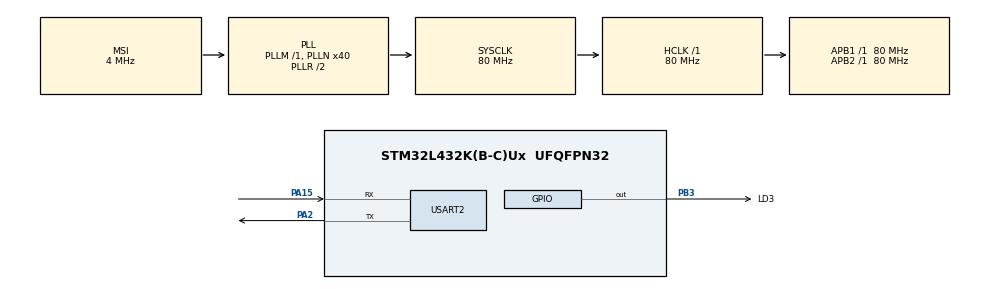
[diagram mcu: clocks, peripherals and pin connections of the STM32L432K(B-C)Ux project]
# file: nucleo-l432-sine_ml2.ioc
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Mcu.Family=STM32L4
Mcu.Name=STM32L432K(B-C)Ux
Mcu.Package=UFQFPN32
NVIC.PriorityGroup=NVIC_PRIORITYGROUP_4
PA13\ (JTMS-SWDIO).Mode=Serial_Wire
PA13\ (JTMS-SWDIO).Signal=SYS_JTMS-SWDIO
PA14\ (JTCK-SWCLK).Mode=Serial_Wire
PA14\ (JTCK-SWCLK).Signal=SYS_JTCK-SWCLK
PA15\ (JTDI).Mode=Asynchronous
PA15\ (JTDI).Signal=USART2_RX
PA2.Mode=Asynchronous
PA2.Signal=USART2_TX
PB3\ (JTDO-TRACESWO).GPIO_Label=LD3
PB3\ (JTDO-TRACESWO).Signal=GPIO_Output
PC14-OSC32_IN\ (PC14).Mode=LSE-External-Oscillator
PC14-OSC32_IN\ (PC14).Signal=RCC_OSC32_IN
PC15-OSC32_OUT\ (PC15).Mode=LSE-External-Oscillator
PC15-OSC32_OUT\ (PC15).Signal=RCC_OSC32_OUT
ProjectManager.HeapSize=0x800
ProjectManager.StackSize=0x800
ProjectManager.TargetToolchain=STM32CubeIDE
RCC.ADCFreq_Value=16000000
RCC.AHBFreq_Value=80000000
RCC.APB1Freq_Value=80000000
RCC.APB1TimFreq_Value=80000000
RCC.APB2Freq_Value=80000000
RCC.APB2TimFreq_Value=80000000
RCC.CortexFreq_Value=80000000
RCC.HCLKFreq_Value=80000000
RCC.HSE_VALUE=8000000
RCC.HSI48_VALUE=48000000
RCC.HSI_VALUE=16000000
RCC.MSI_VALUE=4000000
RCC.PLLN=40
RCC.SYSCLKFreq_VALUE=80000000
RCC.SYSCLKSource=RCC_SYSCLKSOURCE_PLLCLK
RCC.USBFreq_Value=16000000
RCC.VCOOutputFreq_Value=160000000
STMicroelectronics.X-CUBE-AI.10.0.0.ActivationBufferSizeList=1940
STMicroelectronics.X-CUBE-AI.10.0.0.ActivationBuffers=pool0
STMicroelectronics.X-CUBE-AI.10.0.0.ActivationNames=pool0
STMicroelectronics.X-CUBE-AI.10.0.0.ActivationSizes=AI_SINE_MODEL_DATA_ACTIVATION_1_SIZE
STMicroelectronics.X-CUBE-AI.10.0.0.HeapSize=0x800
STMicroelectronics.X-CUBE-AI.10.0.0.InternalRamActivationBufferMaxSize=AI_SINE_MODEL_DATA_ACTIVATIONS_SIZE
STMicroelectronics.X-CUBE-AI.10.0.0.LatestDirectoryUsed-c6a9cc019ab6260dbbfc86d1c0844e88c55a9913909963e01f907c19b2b0253b=C\:\\Users\\bausch\\Downloads
STMicroelectronics.X-CUBE-AI.10.0.0.MaximumNumberOfInputLayer=1
STMicroelectronics.X-CUBE-AI.10.0.0.MaximumNumberOfOutputLayer=1
STMicroelectronics.X-CUBE-AI.10.0.0.MaximumSizeOfInputLayer=1
STMicroelectronics.X-CUBE-AI.10.0.0.MaximumSizeOfOutputLayer=1
STMicroelectronics.X-CUBE-AI.10.0.0.ModelActualCompression-c6a9cc019ab6260dbbfc86d1c0844e88c55a9913909963e01f907c19b2b0253b=0.0
STMicroelectronics.X-CUBE-AI.10.0.0.ModelCompression-c6a9cc019ab6260dbbfc86d1c0844e88c55a9913909963e01f907c19b2b0253b=None
STMicroelectronics.X-CUBE-AI.10.0.0.ModelFlashOccupation-c6a9cc019ab6260dbbfc86d1c0844e88c55a9913909963e01f907c19b2b0253b=10130
STMicroelectronics.X-CUBE-AI.10.0.0.ModelHashList=c6a9cc019ab6260dbbfc86d1c0844e88c55a9913909963e01f907c19b2b0253b
STMicroelectronics.X-CUBE-AI.10.0.0.ModelKind-c6a9cc019ab6260dbbfc86d1c0844e88c55a9913909963e01f907c19b2b0253b=TFLITE
STMicroelectronics.X-CUBE-AI.10.0.0.ModelMacc-c6a9cc019ab6260dbbfc86d1c0844e88c55a9913909963e01f907c19b2b0253b=353
STMicroelectronics.X-CUBE-AI.10.0.0.ModelName-c6a9cc019ab6260dbbfc86d1c0844e88c55a9913909963e01f907c19b2b0253b=sine_model
STMicroelectronics.X-CUBE-AI.10.0.0.ModelNameList=sine_model
STMicroelectronics.X-CUBE-AI.10.0.0.ModelRamOccupation-c6a9cc019ab6260dbbfc86d1c0844e88c55a9913909963e01f907c19b2b0253b=1940
STMicroelectronics.X-CUBE-AI.10.0.0.ModelStructureFile-c6a9cc019ab6260dbbfc86d1c0844e88c55a9913909963e01f907c19b2b0253b=C\:\\Users\\bausch\\Downloads\\sine_model.tflite
STMicroelectronics.X-CUBE-AI.10.0.0.ModelType-c6a9cc019ab6260dbbfc86d1c0844e88c55a9913909963e01f907c19b2b0253b=STM32Cube.AI MCU runtime
STMicroelectronics.X-CUBE-AI.10.0.0.ReadyForCodeGeneration=true
STMicroelectronics.X-CUBE-AI.10.0.0.StackSize=0x800
STMicroelectronics.X-CUBE-AI.10.0.0.WorkingBufferStartAddrList=0xFFFFFFFF
STMicroelectronics.X-CUBE-AI.10.0.0.XAaCUBEAaAICcArtificialOoIntelligenceJjCore=true
STMicroelectronics.X-CUBE-AI.10.0.0.copyWeightToRam=false
STMicroelectronics.X-CUBE-AI.10.0.0.copyWeightToRam-c6a9cc019ab6260dbbfc86d1c0844e88c55a9913909963e01f907c19b2b0253b=false
STMicroelectronics.X-CUBE-AI.10.0.0.customLayerConfigEnabled=false
STMicroelectronics.X-CUBE-AI.10.0.0.customLayerConfigEnabled-c6a9cc019ab6260dbbfc86d1c0844e88c55a9913909963e01f907c19b2b0253b=false
STMicroelectronics.X-CUBE-AI.10.0.0.noOnnxIoTranspose=false
STMicroelectronics.X-CUBE-AI.10.0.0.noOnnxIoTranspose-c6a9cc019ab6260dbbfc86d1c0844e88c55a9913909963e01f907c19b2b0253b=false
STMicroelectronics.X-CUBE-AI.10.0.0.useInputAllocation=true
STMicroelectronics.X-CUBE-AI.10.0.0.useInputAllocation-c6a9cc019ab6260dbbfc86d1c0844e88c55a9913909963e01f907c19b2b0253b=true
STMicroelectronics.X-CUBE-AI.10.0.0.useOutputAllocation=true
STMicroelectronics.X-CUBE-AI.10.0.0.useOutputAllocation-c6a9cc019ab6260dbbfc86d1c0844e88c55a9913909963e01f907c19b2b0253b=true
TIM16.Prescaler=80-1
USART2.VirtualMode-Asynchronous=VM_ASYNC
VP_STMicroelectronics.X-CUBE-AI_VS_ArtificialOoIntelligenceJjXAaCUBEAaAI_10.0.0.Mode=ArtificialOoIntelligenceJjXAaCUBEAaAI
VP_TIM16_VS_ClockSourceINT.Mode=Enable_Timer
board=custom

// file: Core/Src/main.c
/* USER CODE BEGIN Header */
/**
  ******************************************************************************
  * @file           : main.c
  * @brief          : Main program body
  ******************************************************************************
  * @attention
  *
  * Copyright (c) 2025 STMicroelectronics.
  * All rights reserved.
  *
  * This software is licensed under terms that can be found in the LICENSE file
  * in the root directory of this software component.
  * If no LICENSE file comes with this software, it is provided AS-IS.
  *
  ******************************************************************************
  */
/* USER CODE END Header */
#include "main.h"

/* USER CODE BEGIN Includes */
#include <stdio.h>

#include "sine_model.h"
#include "sine_model_data.h"
/* USER CODE END Includes */

TIM_HandleTypeDef htim16;

UART_HandleTypeDef huart2;

/* USER CODE BEGIN PV */
// memory used to hold intermediate values for neural network
AI_ALIGNED(4) ai_u8 activations[AI_SINE_MODEL_DATA_ACTIVATIONS_SIZE];
AI_ALIGNED(4) ai_u8 in_data[AI_SINE_MODEL_IN_1_SIZE_BYTES];
AI_ALIGNED(4) ai_u8 out_data[AI_SINE_MODEL_OUT_1_SIZE_BYTES];
/* USER CODE END PV */

void SystemClock_Config(void);
static void MX_GPIO_Init(void);
static void MX_USART2_UART_Init(void);
static void MX_TIM16_Init(void);

int main(void)
{

  /* USER CODE BEGIN 1 */
  // pointer to model
  ai_handle network = AI_HANDLE_NULL;

  // pointer to structs holding data and info about data
  // like tensor height, width and channels
  ai_buffer *ai_input;
  ai_buffer *ai_output;

  // helper variables
  ai_error err;
  ai_network_report report;
  ai_i32 nbatch;

  /* USER CODE END 1 */

  /* MCU Configuration--------------------------------------------------------*/

  /* Reset of all peripherals, Initializes the Flash interface and the Systick. */
  HAL_Init();

  /* Configure the system clock */
  SystemClock_Config();

  /* USER CODE BEGIN SysInit */
  HAL_Delay(3); // wait until LSE is stable

  /* USER CODE END SysInit */

  /* Initialize all configured peripherals */
  MX_GPIO_Init();
  MX_USART2_UART_Init();
  MX_TIM16_Init();
  /* USER CODE BEGIN 2 */

  printf("STM32 CubeAI Demo: Sinusfunktion\r\n");

  HAL_TIM_Base_Start(&htim16);
  uint32_t timestamp;
  uint32_t duration;

  // pointer to activations
  const ai_handle acts[] = {activations};

  // create instance of neural network
  err = ai_sine_model_create_and_init(&network, acts, NULL);

  // check for errors
  if (err.type != AI_ERROR_NONE) {
      printf("Error: ai_sine_model_create_and_init()\r\n");
  } else {
      printf("Success: model created and initialized\r\n");
  }

  if (ai_sine_model_get_report(network, &report) != true) {
      printf("Error: failed to get report\r\n");
  }

  ai_input  = &report.inputs[0];
  ai_output = &report.outputs[0];

  // link inputs and outputs to the model
  ai_input[0].data  = AI_HANDLE_PTR(in_data);
  ai_output[0].data = AI_HANDLE_PTR(out_data);

  float x_val = 1.5;
  float y_val;

  // convert input variable to ai_float
  for (uint8_t i=0; i < AI_SINE_MODEL_IN_1_SIZE; i++) {
	((ai_float*)in_data)[i] = (ai_float)x_val;
  }

  // Get current timestamp
  timestamp = htim16.Instance->CNT;

  // run inference
  nbatch = ai_sine_model_run(network, ai_input, ai_output);

  // Calc duration
  duration = htim16.Instance->CNT - timestamp;

  if (nbatch != 1) {
	printf("Error: could not run inference\r\n");
  }

  // convert output from model to float
  y_val = ((float*)out_data)[0];

  printf("x=%.2f | y=%.3f | Duration: %.3f ms\r\n", x_val, y_val, (duration/1000.0));

  /* USER CODE END 2 */

  /* Infinite loop */
  while (1)
  {

  }
}

void SystemClock_Config(void)
{
  RCC_OscInitTypeDef RCC_OscInitStruct = {0};
  RCC_ClkInitTypeDef RCC_ClkInitStruct = {0};

  /** Configure the main internal regulator output voltage
  */
  if (HAL_PWREx_ControlVoltageScaling(PWR_REGULATOR_VOLTAGE_SCALE1) != HAL_OK)
  {
    Error_Handler();
  }

  /** Configure LSE Drive Capability
  */
  HAL_PWR_EnableBkUpAccess();
  __HAL_RCC_LSEDRIVE_CONFIG(RCC_LSEDRIVE_LOW);

  /** Initializes the RCC Oscillators according to the specified parameters
  * in the RCC_OscInitTypeDef structure.
  */
  RCC_OscInitStruct.OscillatorType = RCC_OSCILLATORTYPE_LSE|RCC_OSCILLATORTYPE_MSI;
  RCC_OscInitStruct.LSEState = RCC_LSE_ON;
  RCC_OscInitStruct.MSIState = RCC_MSI_ON;
  RCC_OscInitStruct.MSICalibrationValue = 0;
  RCC_OscInitStruct.MSIClockRange = RCC_MSIRANGE_6;
  RCC_OscInitStruct.PLL.PLLState = RCC_PLL_ON;
  RCC_OscInitStruct.PLL.PLLSource = RCC_PLLSOURCE_MSI;
  RCC_OscInitStruct.PLL.PLLM = 1;
  RCC_OscInitStruct.PLL.PLLN = 40;
  RCC_OscInitStruct.PLL.PLLP = RCC_PLLP_DIV7;
  RCC_OscInitStruct.PLL.PLLQ = RCC_PLLQ_DIV2;
  RCC_OscInitStruct.PLL.PLLR = RCC_PLLR_DIV2;
  if (HAL_RCC_OscConfig(&RCC_OscInitStruct) != HAL_OK)
  {
    Error_Handler();
  }

  /** Initializes the CPU, AHB and APB buses clocks
  */
  RCC_ClkInitStruct.ClockType = RCC_CLOCKTYPE_HCLK|RCC_CLOCKTYPE_SYSCLK
                              |RCC_CLOCKTYPE_PCLK1|RCC_CLOCKTYPE_PCLK2;
  RCC_ClkInitStruct.SYSCLKSource = RCC_SYSCLKSOURCE_PLLCLK;
  RCC_ClkInitStruct.AHBCLKDivider = RCC_SYSCLK_DIV1;
  RCC_ClkInitStruct.APB1CLKDivider = RCC_HCLK_DIV1;
  RCC_ClkInitStruct.APB2CLKDivider = RCC_HCLK_DIV1;

  if (HAL_RCC_ClockConfig(&RCC_ClkInitStruct, FLASH_LATENCY_4) != HAL_OK)
  {
    Error_Handler();
  }

  /** Enable MSI Auto calibration
  */
  HAL_RCCEx_EnableMSIPLLMode();
}

static void MX_TIM16_Init(void)
{

  htim16.Instance = TIM16;
  htim16.Init.Prescaler = 80-1;
  htim16.Init.CounterMode = TIM_COUNTERMODE_UP;
  htim16.Init.Period = 65535;
  htim16.Init.ClockDivision = TIM_CLOCKDIVISION_DIV1;
  htim16.Init.RepetitionCounter = 0;
  htim16.Init.AutoReloadPreload = TIM_AUTORELOAD_PRELOAD_DISABLE;
  if (HAL_TIM_Base_Init(&htim16) != HAL_OK)
  {
    Error_Handler();
  }

}

static void MX_USART2_UART_Init(void)
{

  huart2.Instance = USART2;
  huart2.Init.BaudRate = 115200;
  huart2.Init.WordLength = UART_WORDLENGTH_8B;
  huart2.Init.StopBits = UART_STOPBITS_1;
  huart2.Init.Parity = UART_PARITY_NONE;
  huart2.Init.Mode = UART_MODE_TX_RX;
  huart2.Init.HwFlowCtl = UART_HWCONTROL_NONE;
  huart2.Init.OverSampling = UART_OVERSAMPLING_16;
  huart2.Init.OneBitSampling = UART_ONE_BIT_SAMPLE_DISABLE;
  huart2.AdvancedInit.AdvFeatureInit = UART_ADVFEATURE_NO_INIT;
  if (HAL_UART_Init(&huart2) != HAL_OK)
  {
    Error_Handler();
  }

}

static void MX_GPIO_Init(void)
{
  GPIO_InitTypeDef GPIO_InitStruct = {0};

  /* GPIO Ports Clock Enable */
  __HAL_RCC_GPIOC_CLK_ENABLE();
  __HAL_RCC_GPIOA_CLK_ENABLE();
  __HAL_RCC_GPIOB_CLK_ENABLE();

  /*Configure GPIO pin Output Level */
  HAL_GPIO_WritePin(LD3_GPIO_Port, LD3_Pin, GPIO_PIN_RESET);

  /*Configure GPIO pin : LD3_Pin */
  GPIO_InitStruct.Pin = LD3_Pin;
  GPIO_InitStruct.Mode = GPIO_MODE_OUTPUT_PP;
  GPIO_InitStruct.Pull = GPIO_NOPULL;
  GPIO_InitStruct.Speed = GPIO_SPEED_FREQ_LOW;
  HAL_GPIO_Init(LD3_GPIO_Port, &GPIO_InitStruct);

}

/* USER CODE BEGIN 4 */

int _write(int file, char *ptr, int len) {

  HAL_UART_Transmit(&huart2, (uint8_t*) ptr, len, HAL_MAX_DELAY);

  for (int i = 0; i < len; i++) {
    ITM_SendChar(*ptr++);
  }
  return len;
}

/* USER CODE END 4 */

void Error_Handler(void)
{
  __disable_irq();
  while (1)
  {
  }
}
